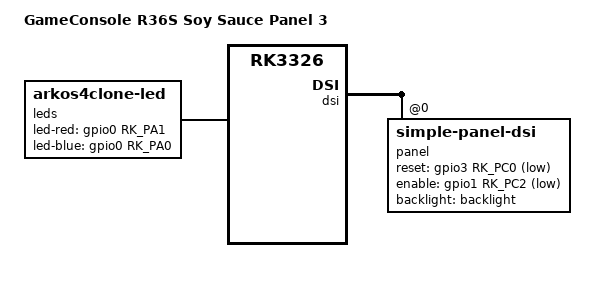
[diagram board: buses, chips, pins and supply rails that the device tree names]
// SPDX-License-Identifier: (GPL-2.0+ OR MIT)
/*
* Copyright (c) 2026 kk&lcdyk
*
* R36S 酱油 Panel 3
*
*/

/dts-v1/;
#include "rk3326-r36s-sauce.dtsi"

/ {
	model = "GameConsole R36S Soy Sauce Panel 3";
	compatible = "rockchip,rk3326-r36s-sauce-panel3-linux", "rockchip,rk3326";
	
	leds: arkos4clone-leds {
		compatible = "arkos4clone-led";
		
		led-red = <&gpio0 RK_PA1 GPIO_ACTIVE_HIGH>;
		led-blue = <&gpio0 RK_PA0 GPIO_ACTIVE_HIGH>;
	};
};

&dsi {
	status = "okay";
	
	panel@0 {
		compatible = "simple-panel-dsi";
		reg = <0>;
		/* pwm1 backlight */
		backlight = <&backlight>;
		/* LCD reset gpio GPIO3.B7 */
		reset-gpios = <&gpio3 RK_PC0 GPIO_ACTIVE_LOW>;
		/* power-supply-gpio GPIO0.B5  */
		enable-gpios = <&gpio1 RK_PC2 GPIO_ACTIVE_LOW>;
		prepare-delay-ms = <100>;
		reset-delay-ms = <50>;
		init-delay-ms = <20>;
		enable-delay-ms = <200>;
		disable-delay-ms = <50>;
		unprepare-delay-ms = <250>;
		width-mm = <71>;
		height-mm = <71>;
		dsi,flags  = <(MIPI_DSI_MODE_VIDEO |
		MIPI_DSI_MODE_VIDEO_BURST |
		MIPI_DSI_MODE_LPM |
		MIPI_DSI_MODE_EOT_PACKET)>;
		dsi,format = <MIPI_DSI_FMT_RGB888>;
		dsi,lanes = <4>;
		panel-init-sequence = <0x390006f0 0xaa559708 0x150002 0xba011500 0x2a1ff15 0x2a0cc 0x150002a4 0xff150002 0xa50b1500 0x2937a15 0x2b602 0x1500029d 0xaa150002 0xe4953900 0x6f0aa55 0x97080115 0x26006 0x15000262 0xc8150002 0x63621500 0x2658015 0x26689 0x15000268 0x91150002 0x69c31500 0x260ff15 0x261ff 0x15000262 0xff150002 0x63ff1500 0x264ff15 0x265ff 0x15000266 0xff150002 0x67ff1500 0x268ff15 0x269ff 0x390003e3 0x5a871500 0x2cf2d15 0x2e951 0x39002db3 0x3f343434 0x2829090b 0xd0f013f 0x34343f3f 0x3f3f3f3f 0x3f3f3f34 0x34342829 0x80a0c0e 0x3f3434 0x3f3f3f3f 0x3f3f3f3f 0x390009a0 0x18055252 0x18045252 0x390006a7 0x11525252 0x5239000d 0xa8000301 0xfb000004 0x1fc0303 0x39000d 0xa9080301 0xf5000802 0x1f50303 0x39000d 0xaa080101 0xf7000800 0x1f80303 0x39000d 0xab000101 0xf9000002 0x1fa0303 0x390008 0xa400080f 0x80a0000 0x390009a6 0x11ff8806 0x11ff8806 0x390008b0 0x22222222 0x2222f415 0x2b727 0x390014f1 0x7f6d6156 0x57484c35 0x4c494864 0x4f574b45 0x38260039 0x14f27f 0x6d615657 0x484c354c 0x4948644f 0x574b4538 0x26003900 0x6e71002 0x7f000015 0x2ed02 0x150002ee 0x22390003 0xe6e83515 0x23500 0x5960111 0x5320129>;
		panel-exit-sequence = <0x5140128 0x50a0110>;
		
		display-timings {
			native-mode = <&timing0>;
			
			// 40.00MHz / (640+60+2+60)×(480+20+4+14) = 762×518 = 101.34 Hz
			timing0: original {
				clock-frequency = <40000000>;
				hactive = <640>;
				vactive = <480>;
				hback-porch = <60>;
				hfront-porch = <60>;
				vback-porch = <14>;
				vfront-porch = <20>;
				hsync-len = <2>;
				vsync-len = <4>;
				hsync-active = <0>;
				vsync-active = <0>;
				de-active = <0>;
				pixelclk-active = <0>;
			};
		};
	};
};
